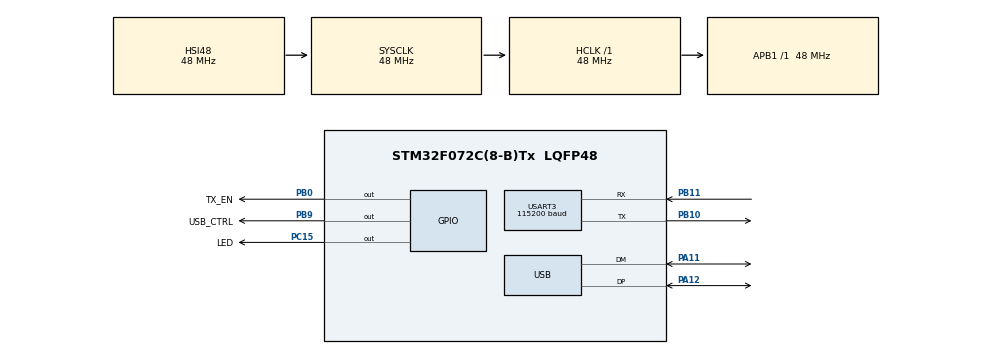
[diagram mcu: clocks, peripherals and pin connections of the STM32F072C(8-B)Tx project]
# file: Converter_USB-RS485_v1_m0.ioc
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Mcu.Family=STM32F0
USB_DEVICE.CLASS_NAME_FS=CDC
PB9.GPIO_Label=USB_CTRL
NVIC.USB_IRQn=true\:0\:0\:false\:false\:true\:false\:true
PB10.Mode=Asynchronous
USB_DEVICE.VirtualModeFS=Cdc_FS
USB_DEVICE.PID_CDC_FS=24853
PB9.GPIO_ModeDefaultOutputPP=GPIO_MODE_OUTPUT_OD
PA11.Mode=Device
PB0.GPIO_Label=TX_EN
PB11.Signal=USART3_RX
PC15-OSC32_OUT.GPIO_Label=LED
RCC.SYSCLKSource=RCC_SYSCLKSOURCE_HSI48
ProjectManager.StackSize=0x400
USART3.VirtualMode-Asynchronous=VM_ASYNC
PA13.Signal=SYS_SWDIO
USB_DEVICE.MANUFACTURER_STRING=Forward
PA12.Signal=USB_DP
USART3.BaudRate=115200
PB11.Mode=Asynchronous
USB_DEVICE.VID=1003
ProjectManager.TargetToolchain=STM32CubeIDE
USB_DEVICE.PRODUCT_STRING_CDC_FS=Converter USB-RS485
NVIC.USART3_4_IRQn=true\:0\:0\:false\:false\:true\:true\:true
RCC.HCLKFreq_Value=48000000
VP_USB_DEVICE_VS_USB_DEVICE_CDC_FS.Mode=CDC_FS
PC15-OSC32_OUT.Signal=GPIO_Output
RCC.AHBFreq_Value=48000000
PB10.Signal=USART3_TX
board=custom
PA14.Mode=Serial_Wire
PA13.Mode=Serial_Wire
Mcu.Name=STM32F072C(8-B)Tx
RCC.SYSCLKFreq_VALUE=48000000
Mcu.Package=LQFP48
PB9.Signal=GPIO_Output
PA12.Mode=Device
PB9.PinState=GPIO_PIN_SET
PA11.Signal=USB_DM
PA14.Signal=SYS_SWCLK
ProjectManager.HeapSize=0x200
RCC.APB1TimFreq_Value=48000000
RCC.APB1Freq_Value=48000000
PB0.Signal=GPIO_Output
USB_DEVICE.VirtualMode=Cdc

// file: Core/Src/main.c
/* USER CODE BEGIN Header */
/**
  ******************************************************************************
  * @file           : main.c
  * @brief          : Main program body
  ******************************************************************************
  * @attention
  *
  * <h2><center>&copy; Copyright (c) 2024 STMicroelectronics.
  * All rights reserved.</center></h2>
  *
  * This software component is licensed by ST under BSD 3-Clause license,
  * the "License"; You may not use this file except in compliance with the
  * License. You may obtain a copy of the License at:
  *                        opensource.org/licenses/BSD-3-Clause
  *
  ******************************************************************************
  */
/* USER CODE END Header */
#include "main.h"
#include "usb_device.h"

/* USER CODE BEGIN Includes */
#include "protection.h"
#include "uart.h"
//#include "uart.h"
/* USER CODE END Includes */

UART_HandleTypeDef huart3;

void SystemClock_Config(void);
static void MX_GPIO_Init(void);
static void MX_USART3_UART_Init(void);

int main(void)
{

  /* MCU Configuration--------------------------------------------------------*/

  /* Reset of all peripherals, Initializes the Flash interface and the Systick. */
  HAL_Init();

  /* Configure the system clock */
  SystemClock_Config();

  /* Initialize all configured peripherals */
  MX_GPIO_Init();
  MX_USART3_UART_Init();
  MX_USB_DEVICE_Init();
  /* USER CODE BEGIN 2 */
  //FlashReadoutProtection();

  LED_GPIO_Port->BSRR = LED_Pin;
  USB_CTRL_GPIO_Port->BSRR = USB_CTRL_Pin << 16;

  start_uart_resive();
  /* USER CODE END 2 */

  /* Infinite loop */
  while (1)
  {

  }
}

void SystemClock_Config(void)
{
  RCC_OscInitTypeDef RCC_OscInitStruct = {0};
  RCC_ClkInitTypeDef RCC_ClkInitStruct = {0};
  RCC_PeriphCLKInitTypeDef PeriphClkInit = {0};

  /** Initializes the RCC Oscillators according to the specified parameters
  * in the RCC_OscInitTypeDef structure.
  */
  RCC_OscInitStruct.OscillatorType = RCC_OSCILLATORTYPE_HSI48;
  RCC_OscInitStruct.HSI48State = RCC_HSI48_ON;
  RCC_OscInitStruct.PLL.PLLState = RCC_PLL_NONE;
  if (HAL_RCC_OscConfig(&RCC_OscInitStruct) != HAL_OK)
  {
    Error_Handler();
  }
  /** Initializes the CPU, AHB and APB buses clocks
  */
  RCC_ClkInitStruct.ClockType = RCC_CLOCKTYPE_HCLK|RCC_CLOCKTYPE_SYSCLK
                              |RCC_CLOCKTYPE_PCLK1;
  RCC_ClkInitStruct.SYSCLKSource = RCC_SYSCLKSOURCE_HSI48;
  RCC_ClkInitStruct.AHBCLKDivider = RCC_SYSCLK_DIV1;
  RCC_ClkInitStruct.APB1CLKDivider = RCC_HCLK_DIV1;

  if (HAL_RCC_ClockConfig(&RCC_ClkInitStruct, FLASH_LATENCY_1) != HAL_OK)
  {
    Error_Handler();
  }
  PeriphClkInit.PeriphClockSelection = RCC_PERIPHCLK_USB;
  PeriphClkInit.UsbClockSelection = RCC_USBCLKSOURCE_HSI48;

  if (HAL_RCCEx_PeriphCLKConfig(&PeriphClkInit) != HAL_OK)
  {
    Error_Handler();
  }
}

static void MX_USART3_UART_Init(void)
{

  huart3.Instance = USART3;
  huart3.Init.BaudRate = 115200;
  huart3.Init.WordLength = UART_WORDLENGTH_8B;
  huart3.Init.StopBits = UART_STOPBITS_1;
  huart3.Init.Parity = UART_PARITY_NONE;
  huart3.Init.Mode = UART_MODE_TX_RX;
  huart3.Init.HwFlowCtl = UART_HWCONTROL_NONE;
  huart3.Init.OverSampling = UART_OVERSAMPLING_16;
  huart3.Init.OneBitSampling = UART_ONE_BIT_SAMPLE_DISABLE;
  huart3.AdvancedInit.AdvFeatureInit = UART_ADVFEATURE_NO_INIT;
  if (HAL_UART_Init(&huart3) != HAL_OK)
  {
    Error_Handler();
  }

}

static void MX_GPIO_Init(void)
{
  GPIO_InitTypeDef GPIO_InitStruct = {0};

  /* GPIO Ports Clock Enable */
  __HAL_RCC_GPIOC_CLK_ENABLE();
  __HAL_RCC_GPIOB_CLK_ENABLE();
  __HAL_RCC_GPIOA_CLK_ENABLE();

  /*Configure GPIO pin Output Level */
  HAL_GPIO_WritePin(LED_GPIO_Port, LED_Pin, GPIO_PIN_RESET);

  /*Configure GPIO pin Output Level */
  HAL_GPIO_WritePin(TX_EN_GPIO_Port, TX_EN_Pin, GPIO_PIN_RESET);

  /*Configure GPIO pin Output Level */
  HAL_GPIO_WritePin(USB_CTRL_GPIO_Port, USB_CTRL_Pin, GPIO_PIN_SET);

  /*Configure GPIO pin : LED_Pin */
  GPIO_InitStruct.Pin = LED_Pin;
  GPIO_InitStruct.Mode = GPIO_MODE_OUTPUT_PP;
  GPIO_InitStruct.Pull = GPIO_NOPULL;
  GPIO_InitStruct.Speed = GPIO_SPEED_FREQ_LOW;
  HAL_GPIO_Init(LED_GPIO_Port, &GPIO_InitStruct);

  /*Configure GPIO pin : TX_EN_Pin */
  GPIO_InitStruct.Pin = TX_EN_Pin;
  GPIO_InitStruct.Mode = GPIO_MODE_OUTPUT_PP;
  GPIO_InitStruct.Pull = GPIO_NOPULL;
  GPIO_InitStruct.Speed = GPIO_SPEED_FREQ_LOW;
  HAL_GPIO_Init(TX_EN_GPIO_Port, &GPIO_InitStruct);

  /*Configure GPIO pin : USB_CTRL_Pin */
  GPIO_InitStruct.Pin = USB_CTRL_Pin;
  GPIO_InitStruct.Mode = GPIO_MODE_OUTPUT_OD;
  GPIO_InitStruct.Pull = GPIO_NOPULL;
  GPIO_InitStruct.Speed = GPIO_SPEED_FREQ_LOW;
  HAL_GPIO_Init(USB_CTRL_GPIO_Port, &GPIO_InitStruct);

}

void Error_Handler(void)
{
  __disable_irq();
  while (1)
  {
  }
}

/************************ (C) COPYRIGHT STMicroelectronics *****END OF FILE****/
